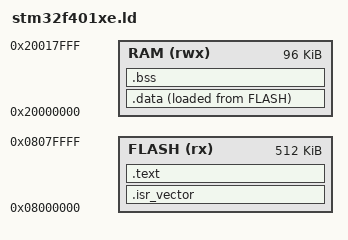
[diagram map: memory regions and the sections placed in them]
/* Linker script for STM32F401xE (512 KB Flash, 96 KB RAM)
 *
 * Adjust MEMORY region sizes if targeting F411RE (512 KB / 128 KB)
 * or F446RE (512 KB / 128 KB) -- only the RAM LENGTH needs changing.
 */

MEMORY
{
    FLASH (rx)  : ORIGIN = 0x08000000, LENGTH = 512K
    RAM   (rwx) : ORIGIN = 0x20000000, LENGTH = 96K
}

/* Stack lives at the top of RAM */
_estack = ORIGIN(RAM) + LENGTH(RAM);

SECTIONS
{
    /* ---- Flash ---- */

    .isr_vector :
    {
        . = ALIGN(4);
        KEEP(*(.isr_vector))
        . = ALIGN(4);
    } >FLASH

    .text :
    {
        . = ALIGN(4);
        *(.text)
        *(.text*)
        *(.rodata)
        *(.rodata*)
        . = ALIGN(4);
        _etext = .;
    } >FLASH

    /* Load address of .data in Flash */
    _sidata = LOADADDR(.data);

    /* ---- RAM ---- */

    .data :
    {
        . = ALIGN(4);
        _sdata = .;
        *(.data)
        *(.data*)
        . = ALIGN(4);
        _edata = .;
    } >RAM AT> FLASH

    .bss :
    {
        . = ALIGN(4);
        _sbss = .;
        *(.bss)
        *(.bss*)
        *(COMMON)
        . = ALIGN(4);
        _ebss = .;
    } >RAM

    /* Discard C library exception-handling metadata (unused with -fno-exceptions) */
    /DISCARD/ :
    {
        *(.ARM.exidx*)
        *(.ARM.extab*)
    }
}
